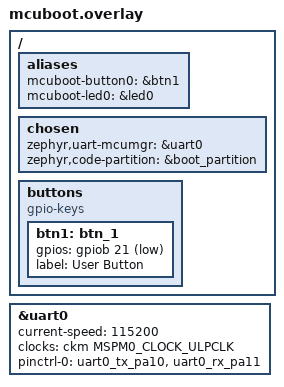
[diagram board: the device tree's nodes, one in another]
/ {
	aliases {
		mcuboot-button0 = &btn1;
		mcuboot-led0 = &led0;
  	};

	chosen {
		zephyr,uart-mcumgr = &uart0;
		zephyr,code-partition = &boot_partition;
	};
	
	buttons {
		compatible = "gpio-keys";
		btn1: btn_1 {
			gpios = <&gpiob 21 (GPIO_ACTIVE_LOW | GPIO_PULL_UP)>;
			label = "User Button";
			status = "okay";
		};
	};
};

&uart0 {
	current-speed = <115200>;
	clocks = <&ckm MSPM0_CLOCK_ULPCLK>;
	pinctrl-0 = <&uart0_tx_pa10 &uart0_rx_pa11>;
    status = "okay";
};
